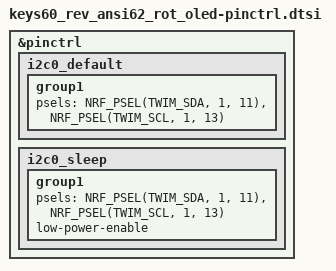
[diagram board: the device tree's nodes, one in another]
/*
 * Copyright (c) 2026 sig (Toxsig)
 *
 * SPDX-License-Identifier: MIT
 */

&pinctrl {
	i2c0_default: i2c0_default {
		group1 {
			psels = <NRF_PSEL(TWIM_SDA, 1, 11)>,
				<NRF_PSEL(TWIM_SCL, 1, 13)>;
		};
	};

	i2c0_sleep: i2c0_sleep {
		group1 {
			psels = <NRF_PSEL(TWIM_SDA, 1, 11)>,
				<NRF_PSEL(TWIM_SCL, 1, 13)>;
			low-power-enable;
		};
	};
};
